# S32K148 register map
Vendor: NXP; Series: S32K; File version: 1.6
CPU: CM4 r0p1, little endian, MPU, FPU, 4 interrupt priority bits
Registers are 32-bit, read-write, reset 0x0 unless marked. A register's access mark holds for its fields unless they carry their own. Offsets are from the block's base; [hi:lo] are bit positions; {n}, {i} and the like mark numbered series; 'fields as' and 'values as' point back to an identical list.

## ADC0 — Analog-to-Digital Converter
Base 0x4003B000; register names take the prefix ADC0_
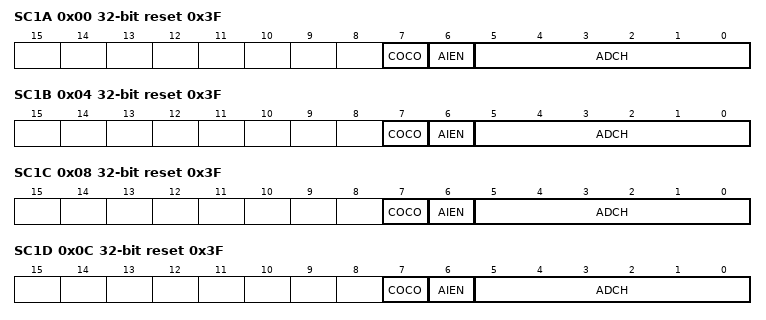
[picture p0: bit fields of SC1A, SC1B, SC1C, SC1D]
0x00 SC1A reset 0x3F — ADC Status and Control Register 1
  [7] COCO ro — Conversion Complete Flag
    0=Conversion is not completed; 1=Conversion is completed
  [6] AIEN — Interrupt Enable
    0=Conversion complete interrupt is disabled; 1=Conversion complete interrupt is enabled
  [5:0] ADCH — Input channel select
    0=Exernal intput channel 0 is selected; {v}=Exernal channel {v} is selected as input (v=1..15); 21=Internal channel 0 is selected as input; 22=Internal channel 1 is selected as input; 23=Internal channel 2 is selected as input; 26=Temp Sensor; 27=Band Gap; 28=Internal channel 3 is selected as input; 29=VREFSH is selected as input. Voltage reference selected is determined by SC2[REFSEL].; 30=VREFSL is selected as input. Voltage reference selected is determined by SC2[REFSEL].; 31=Module is disabled; 32=Internal channel 16 is selected as input; {v}=Exernal channel {v-16} is selected as input (v=33..47); 0b11xxxx=Module is disabled
0x04 SC1B reset 0x3F — ADC Status and Control Register 1
  fields as SC1A
0x08 SC1C reset 0x3F — ADC Status and Control Register 1
  fields as SC1A
0x0C SC1D reset 0x3F — ADC Status and Control Register 1
  fields as SC1A
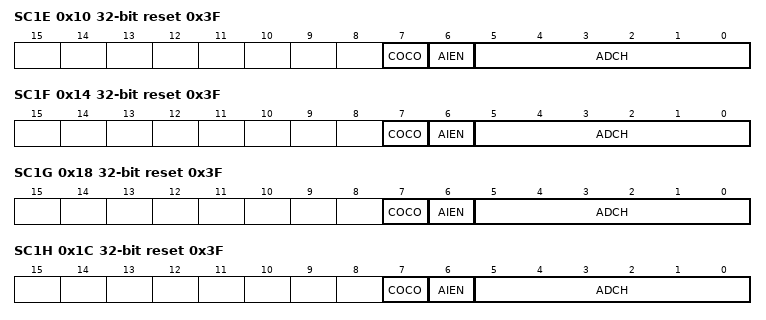
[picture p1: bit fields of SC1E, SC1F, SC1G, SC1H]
0x10 SC1E reset 0x3F — ADC Status and Control Register 1
  fields as SC1A
0x14 SC1F reset 0x3F — ADC Status and Control Register 1
  fields as SC1A
0x18 SC1G reset 0x3F — ADC Status and Control Register 1
  fields as SC1A
0x1C SC1H reset 0x3F — ADC Status and Control Register 1
  fields as SC1A
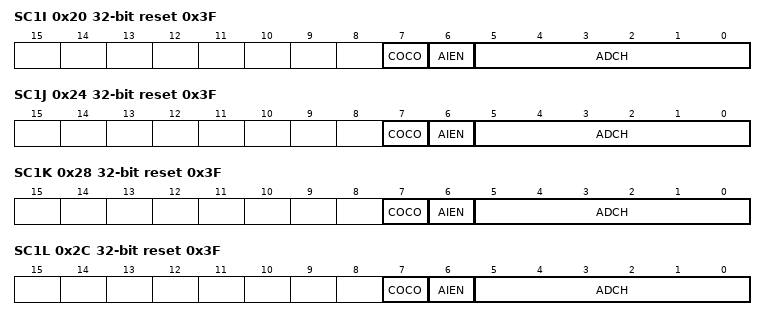
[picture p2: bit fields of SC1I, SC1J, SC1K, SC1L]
0x20 SC1I reset 0x3F — ADC Status and Control Register 1
  fields as SC1A
0x24 SC1J reset 0x3F — ADC Status and Control Register 1
  fields as SC1A
0x28 SC1K reset 0x3F — ADC Status and Control Register 1
  fields as SC1A
0x2C SC1L reset 0x3F — ADC Status and Control Register 1
  fields as SC1A
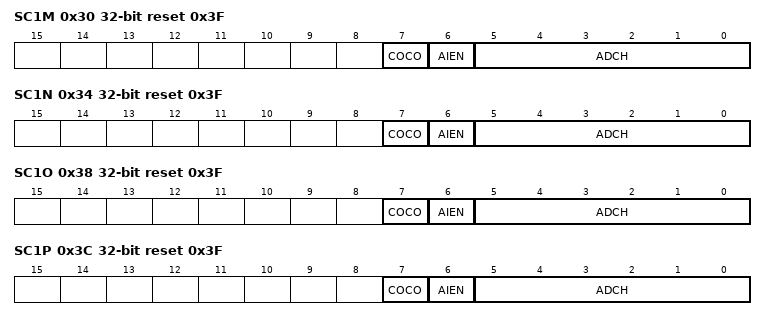
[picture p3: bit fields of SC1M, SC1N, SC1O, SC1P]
0x30 SC1M reset 0x3F — ADC Status and Control Register 1
  fields as SC1A
0x34 SC1N reset 0x3F — ADC Status and Control Register 1
  fields as SC1A
0x38 SC1O reset 0x3F — ADC Status and Control Register 1
  fields as SC1A
0x3C SC1P reset 0x3F — ADC Status and Control Register 1
  fields as SC1A
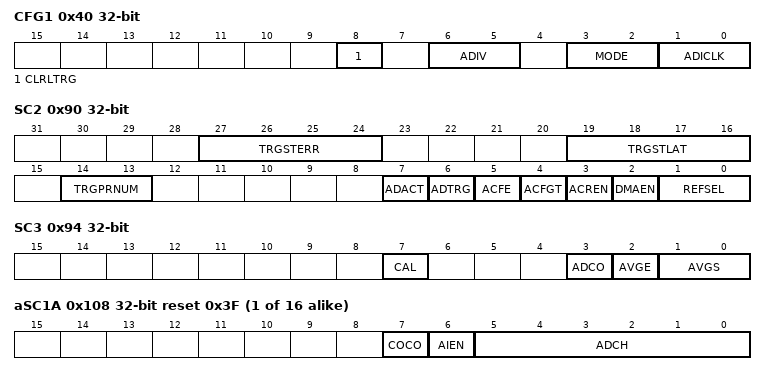
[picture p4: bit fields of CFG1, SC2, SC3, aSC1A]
0x40 CFG1 — ADC Configuration Register 1
  [8] CLRLTRG wo — Clear Latch Trigger in Trigger Handler Block
  [6:5] ADIV — Clock Divide Select
    0=The divide ratio is 1 and the clock rate is input clock; 1=The divide ratio is 2 and the clock rate is (input clock)/2; 2=The divide ratio is 4 and the clock rate is (input clock)/4; 3=The divide ratio is 8 and the clock rate is (input clock)/8
  [3:2] MODE — Conversion mode selection
    0=8-bit conversion; 1=12-bit conversion; 2=10-bit conversion
  [1:0] ADICLK — Input Clock Select
    {v}=Alternate clock {v+1} (ADC_ALTCLK{v+1}) (v=0..3)
0x44 CFG2 reset 0xC — ADC Configuration Register 2
  [7:0] SMPLTS — Sample Time Select
0x48 RA ro — ADC Data Result Registers
  [11:0] D — Data result
0x4C RB ro — ADC Data Result Registers
  [11:0] D — Data result
0x50 RC ro — ADC Data Result Registers
  [11:0] D — Data result
0x54 RD ro — ADC Data Result Registers
  [11:0] D — Data result
0x58 RE ro — ADC Data Result Registers
  [11:0] D — Data result
0x5C RF ro — ADC Data Result Registers
  [11:0] D — Data result
0x60 RG ro — ADC Data Result Registers
  [11:0] D — Data result
0x64 RH ro — ADC Data Result Registers
  [11:0] D — Data result
0x68 RI ro — ADC Data Result Registers
  [11:0] D — Data result
0x6C RJ ro — ADC Data Result Registers
  [11:0] D — Data result
0x70 RK ro — ADC Data Result Registers
  [11:0] D — Data result
0x74 RL ro — ADC Data Result Registers
  [11:0] D — Data result
0x78 RM ro — ADC Data Result Registers
  [11:0] D — Data result
0x7C RN ro — ADC Data Result Registers
  [11:0] D — Data result
0x80 RO ro — ADC Data Result Registers
  [11:0] D — Data result
0x84 RP ro — ADC Data Result Registers
  [11:0] D — Data result
{0x84+4i} CV{i} (i=1..2) — Compare Value Registers
  [15:0] CV — Compare Value.
0x90 SC2 — Status and Control Register 2
  [27:24] TRGSTERR ro — Error in Multiplexed Trigger Request
    0=No error has occurred; 1=An error has occurred
  [19:16] TRGSTLAT ro — Trigger Status
    0=No trigger request has been latched; 1=A trigger request has been latched
  [14:13] TRGPRNUM ro — Trigger Process Number
  [7] ADACT ro — Conversion Active
    0=Conversion not in progress; 1=Conversion in progress
  [6] ADTRG — Conversion Trigger Select
    0=Software trigger selected; 1=Hardware trigger selected
  [5] ACFE — Compare Function Enable
    0=Compare function disabled; 1=Compare function enabled
  [4] ACFGT — Compare Function Greater Than Enable
  [3] ACREN — Compare Function Range Enable
  [2] DMAEN — DMA Enable
    0=DMA is disabled; 1=DMA is enabled and will assert the ADC DMA request during an ADC conversion complete event , which is indicated when any SC1n[COCO] flag is asserted
  [1:0] REFSEL — Voltage Reference Selection
    0=Default voltage reference pin pair, that is, external pins VREFH and VREFL; 1=Alternate reference voltage, that is, VALTH. This voltage may be additional external pin or internal source depending on the MCU configuration. See the chip configuration information for details specific to this MCU.
0x94 SC3 — Status and Control Register 3
  [7] CAL — Calibration
  [3] ADCO — Continuous Conversion Enable
    0=One conversion will be performed (or one set of conversions, if AVGE is set) after a conversion is initiated; 1=Continuous conversions will be performed (or continuous sets of conversions, if AVGE is set) after a conversion is initiated
  [2] AVGE — Hardware Average Enable
    0=Hardware average function disabled; 1=Hardware average function enabled
  [1:0] AVGS — Hardware Average Select
    0=4 samples averaged; 1=8 samples averaged; 2=16 samples averaged; 3=32 samples averaged
0x98 BASE_OFS reset 0x40 — BASE Offset Register
  [7:0] BA_OFS — Base Offset Error Correction Value
0x9C OFS — ADC Offset Correction Register
  [15:0] OFS — Offset Error Correction Value
0xA0 USR_OFS — USER Offset Correction Register
  [7:0] USR_OFS — USER Offset Error Correction Value
0xA4 XOFS reset 0x30 — ADC X Offset Correction Register
  [5:0] XOFS — X offset error correction value
0xA8 YOFS reset 0x37 — ADC Y Offset Correction Register
  [7:0] YOFS — Y offset error correction value
0xAC G reset 0x2F0 — ADC Gain Register
  [10:0] G — Gain error adjustment factor for the overall conversion
0xB0 UG reset 0x4 — ADC User Gain Register
  [9:0] UG — User gain error correction value
0xB4 CLPS reset 0x2E — ADC General Calibration Value Register S
  [6:0] CLPS — Calibration Value
0xB8 CLP3 reset 0x180 — ADC Plus-Side General Calibration Value Register 3
  [9:0] CLP3 — Calibration Value
0xBC CLP2 reset 0xB8 — ADC Plus-Side General Calibration Value Register 2
  [9:0] CLP2 — Calibration Value
0xC0 CLP1 reset 0x5C — ADC Plus-Side General Calibration Value Register 1
  [8:0] CLP1 — Calibration Value
0xC4 CLP0 reset 0x2E — ADC Plus-Side General Calibration Value Register 0
  [7:0] CLP0 — Calibration Value
0xC8 CLPX — ADC Plus-Side General Calibration Value Register X
  [6:0] CLPX — Calibration Value
0xCC CLP9 — ADC Plus-Side General Calibration Value Register 9
  [6:0] CLP9 — Calibration Value
0xD0 CLPS_OFS — ADC General Calibration Offset Value Register S
  [3:0] CLPS_OFS — CLPS Offset
0xD4 CLP3_OFS — ADC Plus-Side General Calibration Offset Value Register 3
  [3:0] CLP3_OFS — CLP3 Offset
0xD8 CLP2_OFS — ADC Plus-Side General Calibration Offset Value Register 2
  [3:0] CLP2_OFS — CLP2 Offset
0xDC CLP1_OFS — ADC Plus-Side General Calibration Offset Value Register 1
  [3:0] CLP1_OFS — CLP1 Offset
0xE0 CLP0_OFS — ADC Plus-Side General Calibration Offset Value Register 0
  [3:0] CLP0_OFS — CLP0 Offset
0xE4 CLPX_OFS reset 0x440 — ADC Plus-Side General Calibration Offset Value Register X
  [11:0] CLPX_OFS — CLPX Offset
0xE8 CLP9_OFS reset 0x240 — ADC Plus-Side General Calibration Offset Value Register 9
  [11:0] CLP9_OFS — CLP9 Offset
0x108 aSC1{x} (x=A,B,C,D,E,F,G,H,I,J,K,L,M,N,O,P; step 0x4) reset 0x3F — ADC Status and Control Register 1 (alias)
  fields as SC1A
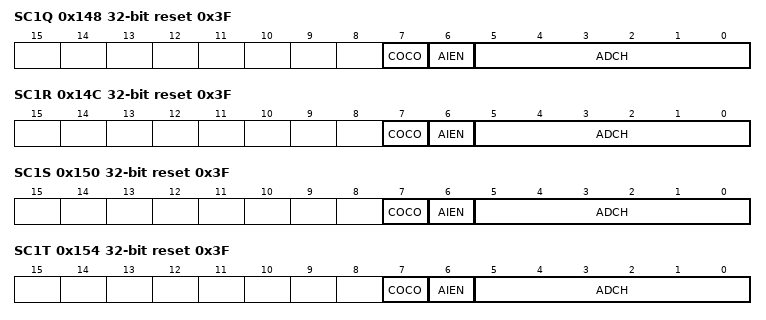
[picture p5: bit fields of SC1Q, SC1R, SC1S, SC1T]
0x148 SC1Q reset 0x3F — ADC Status and Control Register 1
  fields as SC1A
0x14C SC1R reset 0x3F — ADC Status and Control Register 1
  fields as SC1A
0x150 SC1S reset 0x3F — ADC Status and Control Register 1
  fields as SC1A
0x154 SC1T reset 0x3F — ADC Status and Control Register 1
  fields as SC1A
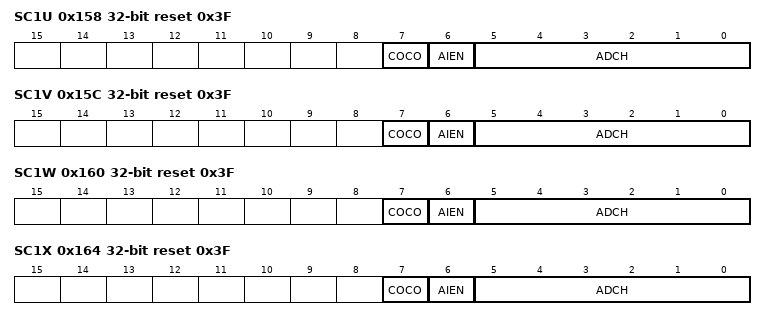
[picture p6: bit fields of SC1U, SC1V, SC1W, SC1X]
0x158 SC1U reset 0x3F — ADC Status and Control Register 1
  fields as SC1A
0x15C SC1V reset 0x3F — ADC Status and Control Register 1
  fields as SC1A
0x160 SC1W reset 0x3F — ADC Status and Control Register 1
  fields as SC1A
0x164 SC1X reset 0x3F — ADC Status and Control Register 1
  fields as SC1A
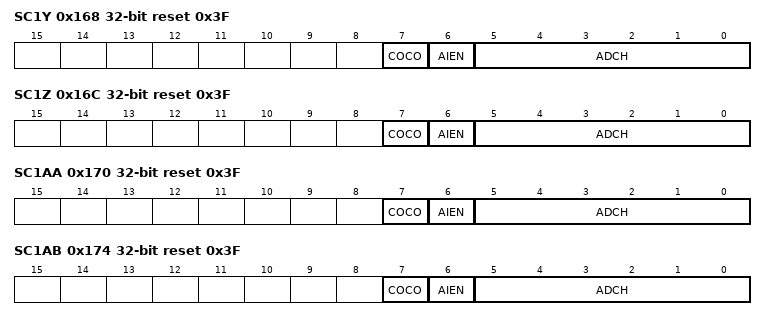
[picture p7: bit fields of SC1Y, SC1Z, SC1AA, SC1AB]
0x168 SC1Y reset 0x3F — ADC Status and Control Register 1
  fields as SC1A
0x16C SC1Z reset 0x3F — ADC Status and Control Register 1
  fields as SC1A
0x170 SC1AA reset 0x3F — ADC Status and Control Register 1
  fields as SC1A
0x174 SC1AB reset 0x3F — ADC Status and Control Register 1
  fields as SC1A
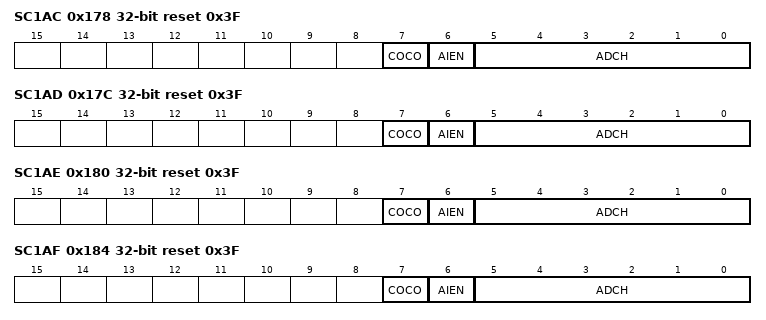
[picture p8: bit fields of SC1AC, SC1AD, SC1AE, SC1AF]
0x178 SC1AC reset 0x3F — ADC Status and Control Register 1
  fields as SC1A
0x17C SC1AD reset 0x3F — ADC Status and Control Register 1
  fields as SC1A
0x180 SC1AE reset 0x3F — ADC Status and Control Register 1
  fields as SC1A
0x184 SC1AF reset 0x3F — ADC Status and Control Register 1
  fields as SC1A
0x188 aR{x} (x=A,B,C,D,E,F,G,H,I,J,K,L,M,N,O,P; step 0x4) ro — ADC Data Result Registers (alias)
  [11:0] D — Data result
0x1C8 RQ ro — ADC Data Result Registers
  [11:0] D — Data result
0x1CC RR ro — ADC Data Result Registers
  [11:0] D — Data result
0x1D0 RS ro — ADC Data Result Registers
  [11:0] D — Data result
0x1D4 RT ro — ADC Data Result Registers
  [11:0] D — Data result
0x1D8 RU ro — ADC Data Result Registers
  [11:0] D — Data result
0x1DC RV ro — ADC Data Result Registers
  [11:0] D — Data result
0x1E0 RW ro — ADC Data Result Registers
  [11:0] D — Data result
0x1E4 RX ro — ADC Data Result Registers
  [11:0] D — Data result
0x1E8 RY ro — ADC Data Result Registers
  [11:0] D — Data result
0x1EC RZ ro — ADC Data Result Registers
  [11:0] D — Data result
0x1F0 RAA ro — ADC Data Result Registers
  [11:0] D — Data result
0x1F4 RAB ro — ADC Data Result Registers
  [11:0] D — Data result
0x1F8 RAC ro — ADC Data Result Registers
  [11:0] D — Data result
0x1FC RAD ro — ADC Data Result Registers
  [11:0] D — Data result
0x200 RAE ro — ADC Data Result Registers
  [11:0] D — Data result
0x204 RAF ro — ADC Data Result Registers
  [11:0] D — Data result

## ADC1 — Analog-to-Digital Converter
Base 0x40027000; register names take the prefix ADC1_
Registers as ADC0.
